VERSION ""

NS_ :

BS_:

BU_: XXX

BO_ 2684348833 EEC1: 8 Vector__XXX
 SG_ EngineSpeed : 24|16@1+ (0.125,0) [0|8031.875] "rpm" Vector__XXX

BO_ 136 CRUISE_RELATED: 8 XXX
 SG_ CRUISE_TORQUE_RELATED_INV : 2|9@0+ (1,0) [0|4000] "" XXX
 SG_ ENGINE_TORQUE_RELATED : 45|16@0+ (1,0) [0|50000] "" XXX

BO_ 139 STEER_ANGLE: 48 XXX
 SG_ STEER_ANGLE : 55|16@0+ (0.05,0) [0|500] "" XXX
 SG_ STEER_ANGLE_REPEAT : 208|16@0+ (0.05,0) [0|500] "" XXX

BO_ 140 PEDAL_THROTTLE: 48 XXX
 SG_ ACCEL_PEDAL_POSITION: 43|10@0+ (1,0) [0|1000] "" XXX
 SG_ ACCEL_PEDAL_POSITION_REPEAT: 49|10@0+ (1,0) [0|200] "" XXX
 SG_ RPM_RELATED: 86|12@0+ (0.05,0) [0|4000] "" XXX
 SG_ WHEEL_TORQUE_CMD_RELATED: 139|16@0+ (0.05,0) [0|100000] "" XXX
 SG_ RPM: 167|16@0+ (0.14285,0) [0|100000] "" XXX
 SG_ WHEEL_TORQUE_CMD_RELATED_2: 183|10@0+ (0.05,0) [0|100000] "" XXX

BO_ 141 STEERING_WHEEL: 24 XXX
 SG_ STEER_ANGLE: 55|18@0+ (1,0) [0|140000] "" XXX
 SG_ STEER_RATE: 66|12@0+ (1,0) [0|4000] "" XXX
 SG_ STEER_RELATED_YAW: 86|11@0+ (1,0) [0|1000] "" XXX

BO_ 168 STEERING_2: 24 XXX
 SG_ STEER_ANGLE: 55|12@0+ (1,0) [0|140000] "" XXX
 SG_ STEER_RATE: 79|16@0+ (1,0) [0|4000] "" XXX

BO_ 286 TWO_EIGHTY_SIX: 4 XXX
 SG_ WHEEL_TORQUE_CMD : 5|15@0+ (1,0) [0|100] "" XXX

BO_ 303 SPEED: 24 XXX
 SG_ WHEEL_TORQUE: 60|12@0+ (1,0) [0|4000] "" XXX
 SG_ SPEED : 77|12@0+ (0.05,0) [0|65535] "kph" XXX

BO_ 308 CRUISE: 64 XXX
 SG_ CRUISE_TORQUE_STATE : 57|4@0+ (1,0) [0|16] "" XXX
 SG_ WHEEL_TORQUE_CMD : 68|12@0+ (1,0) [0|4000] "" XXX
 SG_ STEER_ANGLE_BUT_NOT : 151|16@0+ (1,0) [0|40000] "" XXX
 SG_ BRAKE_TORQUE_ACTIVE : 160|1@0+ (1,0) [0|1] "" XXX
 SG_ BRAKE_TORQUE_CMD : 170|10@0+ (1,0) [0|1000] "" XXX
 SG_ CRUISE_STATE : 306|5@0+ (1,0) [0|32] "" XXX
 SG_ CRUISE_ENGAGED : 321|1@0+ (1,0) [0|1] "" XXX

BO_ 427 ACCEL_STEER: 64 XXX
 SG_ MYSTERY_STATE : 52|4@0+ (1,0) [0|16] "" XXX
 SG_ STEERING_RATE : 63|7@0+ (1,-75) [0|40000] "" XXX
 SG_ STEER_ANGLE : 71|12@0+ (1,-1500) [0|4000] "" XXX
 SG_ ACCEL_X : 231|12@0+ (0.1,-2000) [0|4000] "" XXX
 SG_ ACCEL_X_REPEAT : 235|12@0+ (0.1,-2000) [0|4000] "" XXX
 SG_ YAW : 255|12@0+ (0.1,-2000) [0|4000] "" XXX
 SG_ YAW_REPEAT : 259|12@0+ (0.1,-2000) [0|4000] "" XXX
 SG_ STEER_ANGLE_REPEAT : 315|12@0+ (1,-3050) [0|4000] "" XXX
 SG_ STEER_ANGLE_BUT_NOT : 343|15@0+ (1,0) [0|40000] "" XXX
 SG_ MYSTERY_STATE2 : 344|1@0+ (1,0) [0|1] "" XXX
 SG_ STEER_ANGLE_REPEAT_AGAIN : 359|11@0+ (1,-1000) [0|2000] "" XXX

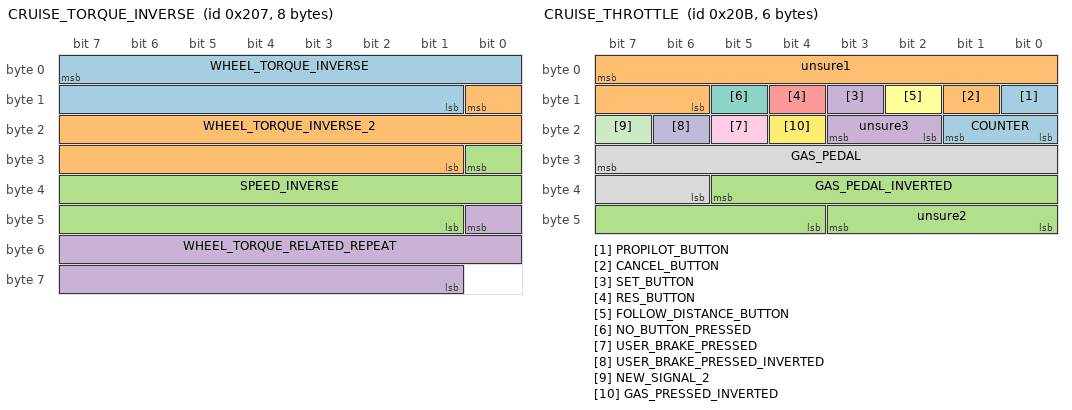
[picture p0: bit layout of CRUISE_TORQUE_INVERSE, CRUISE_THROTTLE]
BO_ 519 CRUISE_TORQUE_INVERSE: 8 XXX
 SG_ WHEEL_TORQUE_INVERSE : 7|15@0+ (1,0) [0|2000] "" XXX
 SG_ WHEEL_TORQUE_INVERSE_2 : 8|16@0+ (1,0) [0|20000] "" XXX
 SG_ SPEED_INVERSE : 24|16@0+ (1,0) [0|60000] "" XXX
 SG_ WHEEL_TORQUE_RELATED_REPEAT : 40|16@0+ (1,0) [0|60000] "" XXX

BO_ 523 CRUISE_THROTTLE: 6 XXX
 SG_ PROPILOT_BUTTON : 8|1@0+ (1,0) [0|1] "" XXX
 SG_ CANCEL_BUTTON : 9|1@0+ (1,0) [0|1] "" XXX
 SG_ GAS_PEDAL_INVERTED : 37|10@0+ (1,0) [0|1023] "" XXX
 SG_ SET_BUTTON : 11|1@0+ (1,0) [0|1] "" XXX
 SG_ RES_BUTTON : 12|1@0+ (1,0) [0|1] "" XXX
 SG_ FOLLOW_DISTANCE_BUTTON : 10|1@0+ (1,0) [0|1] "" XXX
 SG_ NO_BUTTON_PRESSED : 13|1@0+ (1,0) [0|1] "" XXX
 SG_ GAS_PEDAL : 31|10@0+ (1,0) [0|255] "" XXX
 SG_ USER_BRAKE_PRESSED : 21|1@0+ (1,0) [0|1] "" XXX
 SG_ USER_BRAKE_PRESSED_INVERTED : 22|1@0+ (1,0) [0|3] "" XXX
 SG_ NEW_SIGNAL_2 : 23|1@0+ (1,0) [0|1] "" XXX
 SG_ GAS_PRESSED_INVERTED : 20|1@0+ (1,0) [0|255] "" XXX
 SG_ COUNTER : 17|2@0+ (1,0) [0|3] "" XXX
 SG_ unsure1 : 7|10@0+ (1,0) [0|1023] "" XXX
 SG_ unsure2 : 43|4@0+ (1,0) [0|1] "" XXX
 SG_ unsure3 : 19|2@0+ (1,0) [0|3] "" XXX

BO_ 550 WHEEL_ENCODERS: 64 XXX
 SG_ WHEEL_SPEED_FL : 111|16@0+ (0.0057,0) [0|65535] "" XXX
 SG_ WHEEL_SPEED_FR : 127|16@0+ (0.0057,0) [0|65535] "" XXX
 SG_ WHEEL_SPEED_FRONT : 143|16@0+ (0.01,0) [0|65535] "" XXX
 SG_ WHEEL_SPEED_RR : 287|16@0+ (0.0057,0) [0|65535] "" XXX
 SG_ WHEEL_SPEED_RL : 303|16@0+ (0.0057,0) [0|65535] "" XXX
 SG_ WHEEL_SPEED_REAR : 319|16@0+ (0.01,0) [0|65535] "" XXX

BO_ 689 PROPILOT_HUD: 8 XXX
 SG_ LARGE_WARNING_FLASHING : 9|1@0+ (1,0) [0|1] "" XXX
 SG_ SIDE_RADAR_ERROR_FLASHING1 : 10|1@0+ (1,0) [0|1] "" XXX
 SG_ SIDE_RADAR_ERROR_FLASHING2 : 11|1@0+ (1,0) [0|1] "" XXX
 SG_ RIGHT_LANE_YELLOW_FLASH : 12|1@0+ (1,0) [0|1] "" XXX
 SG_ LEFT_LANE_YELLOW_FLASH : 13|1@0+ (1,0) [0|1] "" XXX
 SG_ LEAD_CAR : 14|1@0+ (1,0) [0|1] "" XXX
 SG_ LEAD_CAR_ERROR : 15|1@0+ (1,0) [0|1] "" XXX
 SG_ FRONT_RADAR_ERROR : 16|1@0+ (1,0) [0|1] "" XXX
 SG_ FRONT_RADAR_ERROR_FLASHING : 17|1@0+ (1,0) [0|1] "" XXX
 SG_ RIGHT_LANE_GREEN : 24|1@0+ (1,0) [0|1] "" XXX
 SG_ LEFT_LANE_GREEN : 25|1@0+ (1,0) [0|1] "" XXX
 SG_ SIDE_RADAR_ERROR_FLASHING3 : 27|1@0+ (1,0) [0|1] "" XXX
 SG_ LKAS_ERROR_FLASHING : 29|1@0+ (1,0) [0|1] "" XXX
 SG_ SAFETY_SHIELD_ACTIVE : 44|1@0+ (1,0) [0|1] "" XXX
 SG_ LARGE_STEERING_WHEEL_ICON : 61|2@0+ (1,0) [0|3] "" XXX
 SG_ RIGHT_LANE_GREEN_FLASH : 62|1@0+ (1,0) [0|1] "" XXX
 SG_ LEFT_LANE_GREEN_FLASH : 63|1@0+ (1,0) [0|1] "" XXX
 SG_ FOLLOW_DISTANCE : 3|2@0+ (1,0) [0|3] "" XXX
 SG_ AUDIBLE_TONE : 47|3@0+ (1,0) [0|8] "" XXX
 SG_ SPEED_SET_ICON : 7|2@0+ (1,0) [0|3] "" XXX
 SG_ SMALL_STEERING_WHEEL_ICON : 42|3@0+ (1,0) [0|7] "" XXX
 SG_ SET_SPEED : 39|8@0+ (1,0) [0|255] "" XXX
 SG_ unknown02 : 1|2@0+ (1,0) [0|3] "" XXX
 SG_ unknown05 : 5|2@0+ (1,0) [0|3] "" XXX
 SG_ unknown08 : 8|7@0+ (1,0) [0|63] "" XXX
 SG_ unknown26 : 26|1@0+ (1,0) [0|1] "" XXX
 SG_ unknown28 : 28|1@0+ (1,0) [0|1] "" XXX
 SG_ unknown31 : 31|2@0+ (1,0) [0|3] "" XXX
 SG_ unknown43 : 43|1@0+ (1,0) [0|1] "" XXX
 SG_ unknown55 : 55|8@0+ (1,0) [0|63] "" XXX
 SG_ unknown59 : 59|4@0+ (1,0) [0|15] "" XXX

BO_ 771 SONAR : 64 XXX
 SG_ SONAR1 : 135|6@0+ (0.0833,0) [0|300] "" XXX
 SG_ SONAR2 : 143|6@0+ (0.0833,0) [0|300] "" XXX
 SG_ SONAR3 : 151|6@0+ (0.0833,0) [0|300] "" XXX
 SG_ SONAR4 : 159|6@0+ (0.0833,0) [0|300] "" XXX
 SG_ SONAR5 : 167|6@0+ (0.0833,0) [0|300] "" XXX
 SG_ SONAR6 : 175|6@0+ (0.0833,0) [0|300] "" XXX

 SG_ SONAR7 : 223|6@0+ (0.0833,0) [0|300] "" XXX
 SG_ SONAR8 : 231|6@0+ (0.0833,0) [0|300] "" XXX
 SG_ SONAR9 : 239|6@0+ (0.0833,0) [0|300] "" XXX
 SG_ SONAR10 : 247|6@0+ (0.0833,0) [0|300] "" XXX
 SG_ SONAR11 : 255|6@0+ (0.0833,0) [0|300] "" XXX
 SG_ SONAR12 : 263|6@0+ (0.0833,0) [0|300] "" XXX

 SG_ SONAR13 : 311|6@0+ (0.0833,0) [0|300] "" XXX
 SG_ SONAR14 : 319|6@0+ (0.0833,0) [0|300] "" XXX
 SG_ SONAR15 : 327|6@0+ (0.0833,0) [0|300] "" XXX
 SG_ SONAR16 : 335|6@0+ (0.0833,0) [0|300] "" XXX
 SG_ SONAR17 : 343|6@0+ (0.0833,0) [0|300] "" XXX
 SG_ SONAR18 : 351|6@0+ (0.0833,0) [0|300] "" XXX
 SG_ SONAR19 : 359|6@0+ (0.0833,0) [0|300] "" XXX
 SG_ SONAR20 : 367|6@0+ (0.0833,0) [0|300] "" XXX

BO_ 768 STEER_TORQUE_SENSOR2: 2 XXX
 SG_ STEERING_TORQUE : 6|7@0+ (1,0) [0|127] "" XXX
 SG_ STEERING_PRESSED : 15|1@0+ (-1,1) [0|7] "" XXX

BO_ 783 CRUISE_STATE: 3 XXX
 SG_ CRUISE_ENABLED : 3|1@0+ (1,0) [0|1] "" XXX

BO_ 1055 GEARBOX: 2 XXX
 SG_ SPORTS_MODE : 13|1@0+ (1,0) [0|1] "" XXX
 SG_ GEAR_SHIFTER : 5|3@0+ (1,0) [0|255] "" XXX

BO_ 1081 ODOMETER: 6 XXX
 SG_ UNKNOWN1 : 7|8@0+ (1,-75) [0|200] "" XXX
 SG_ ODOMETER : 31|12@0+ (1,0) [0|1000000] "m" XXX

BO_ 1105 UNKNOWN_STATE : 24 XXX
 SG_ MYSTERY_NOISY_DISCRETE_STATE : 64|4@0+ (1,0) [0|100] "" XXX

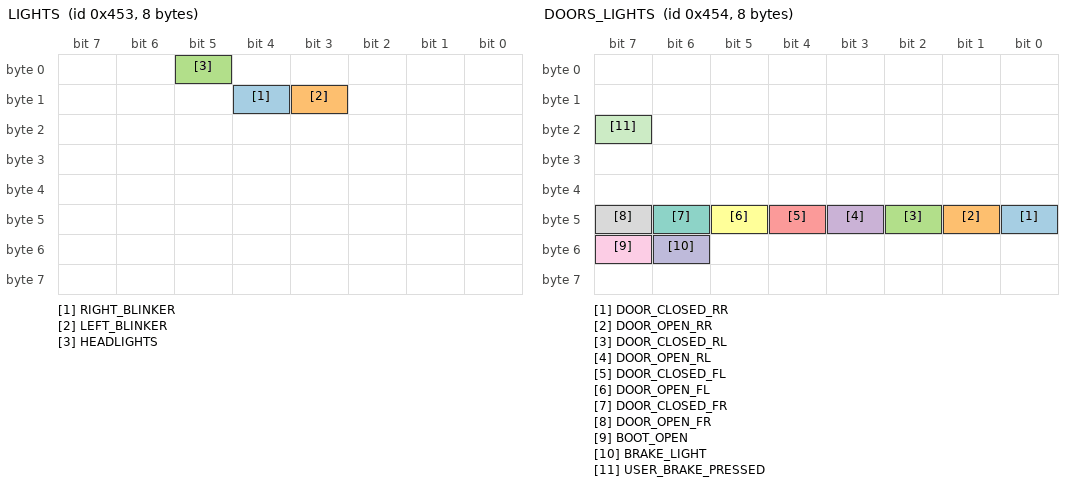
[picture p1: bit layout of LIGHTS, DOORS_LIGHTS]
BO_ 1107 LIGHTS: 8 XXX
 SG_ RIGHT_BLINKER : 12|1@0+ (1,0) [0|1] "" XXX
 SG_ LEFT_BLINKER : 11|1@0+ (1,0) [0|1] "" XXX
 SG_ HEADLIGHTS : 5|1@0+ (1,0) [0|1] "" XXX

BO_ 1108 DOORS_LIGHTS: 8 XXX
 SG_ DOOR_CLOSED_RR : 40|1@0+ (1,0) [0|1] "" XXX
 SG_ DOOR_OPEN_RR : 41|1@0+ (1,0) [0|1] "" XXX
 SG_ DOOR_CLOSED_RL : 42|1@0+ (1,0) [0|1] "" XXX
 SG_ DOOR_OPEN_RL : 43|1@0+ (1,0) [0|1] "" XXX
 SG_ DOOR_CLOSED_FL : 44|1@0+ (1,0) [0|1] "" XXX
 SG_ DOOR_OPEN_FL : 45|1@0+ (1,0) [0|1] "" XXX
 SG_ DOOR_CLOSED_FR : 46|1@0+ (1,0) [0|3] "" XXX
 SG_ DOOR_OPEN_FR : 47|1@0+ (1,0) [0|3] "" XXX
 SG_ BOOT_OPEN : 55|1@0+ (1,0) [0|1] "" XXX
 SG_ BRAKE_LIGHT : 54|1@0+ (1,0) [0|1] "" XXX
 SG_ USER_BRAKE_PRESSED : 23|1@0+ (1,0) [0|1] "" XXX

BO_ 1119 LKAS_SETTINGS: 20 XXX
 SG_ LKAS_LDW_ON : 48|1@0+ (1,0) [0|1] "" XXX

BO_ 1228 PROPILOT_HUD_INFO_MSG: 8 XXX
 SG_ NA_HIGH_ACCEL_TEMP : 0|1@0+ (1,0) [0|1] "" XXX
 SG_ SIDE_RADAR_NA_HIGH_CABIN_TEMP : 8|1@0+ (1,0) [0|1] "" XXX
 SG_ SIDE_RADAR_MALFUNCTION : 11|1@0+ (1,0) [0|1] "" XXX
 SG_ LKAS_MALFUNCTION : 12|1@0+ (1,0) [0|1] "" XXX
 SG_ FRONT_RADAR_MALFUNCTION : 13|1@0+ (1,0) [0|1] "" XXX
 SG_ SIDE_RADAR_NA_CLEAN_REAR_CAMERA : 14|1@0+ (1,0) [0|1] "" XXX
 SG_ NA_POOR_ROAD_CONDITIONS : 16|1@0+ (1,0) [0|1] "" XXX
 SG_ CURRENTLY_UNAVAILABLE : 17|1@0+ (1,0) [0|1] "" XXX
 SG_ SAFETY_SHIELD_OFF : 18|1@0+ (1,0) [0|1] "" XXX
 SG_ FRONT_COLLISION_NA_FRONT_RADAR_OBSTRUCTION : 20|1@0+ (1,0) [0|1] "" XXX
 SG_ PEDAL_MISSAPPLICATION_SYSTEM_ACTIVATED : 24|1@0+ (1,0) [0|1] "" XXX
 SG_ SIDE_IMPACT_NA_RADAR_OBSTRUCTION : 25|1@0+ (1,0) [0|1] "" XXX
 SG_ WARNING_DO_NOT_ENTER : 33|1@0+ (1,0) [0|1] "" XXX
 SG_ SIDE_IMPACT_SYSTEM_OFF : 34|1@0+ (1,0) [0|1] "" XXX
 SG_ SIDE_IMPACT_MALFUNCTION : 35|1@0+ (1,0) [0|1] "" XXX
 SG_ FRONT_COLLISION_MALFUNCTION : 36|1@0+ (1,0) [0|1] "" XXX
 SG_ SIDE_RADAR_MALFUNCTION2 : 37|1@0+ (1,0) [0|1] "" XXX
 SG_ LKAS_MALFUNCTION2 : 38|1@0+ (1,0) [0|1] "" XXX
 SG_ FRONT_RADAR_MALFUNCTION2 : 39|1@0+ (1,0) [0|1] "" XXX
 SG_ PROPILOT_NA_MSGS : 42|3@0+ (1,0) [0|7] "" XXX
 SG_ BOTTOM_MSG : 45|3@0+ (1,0) [0|7] "" XXX
 SG_ HANDS_ON_WHEEL_WARNING : 47|1@0+ (1,0) [0|1] "" XXX
 SG_ WARNING_STEP_ON_BRAKE_NOW : 51|1@0+ (1,0) [0|1] "" XXX
 SG_ PROPILOT_NA_FRONT_CAMERA_OBSTRUCTED : 52|1@0+ (1,0) [0|1] "" XXX
 SG_ PROPILOT_NA_HIGH_CABIN_TEMP : 53|1@0+ (1,0) [0|1] "" XXX
 SG_ WARNING_PROPILOT_MALFUNCTION : 54|1@0+ (1,0) [0|3] "" XXX
 SG_ ACC_UNAVAILABLE_HIGH_CABIN_TEMP : 62|1@0+ (1,0) [0|1] "" XXX
 SG_ ACC_NA_FRONT_CAMERA_IMPARED : 63|1@0+ (1,0) [0|1] "" XXX
 SG_ unknown07 : 7|7@0+ (1,0) [0|127] "" XXX
 SG_ unknown10 : 10|2@0+ (1,0) [0|3] "" XXX
 SG_ unknown15 : 15|1@0+ (1,0) [0|1] "" XXX
 SG_ unknown23 : 23|3@0+ (1,0) [0|7] "" XXX
 SG_ unknown19 : 19|1@0+ (1,0) [0|1] "" XXX
 SG_ unknown31 : 31|6@0+ (1,0) [0|63] "" XXX
 SG_ unknown32 : 32|1@0+ (1,0) [0|1] "" XXX
 SG_ unknown46 : 46|1@0+ (1,0) [0|1] "" XXX
 SG_ unknown50 : 50|3@0+ (1,0) [0|7] "" XXX
 SG_ unknown55 : 55|1@0+ (1,0) [0|1] "" XXX
 SG_ unknown61 : 61|6@0+ (1,0) [0|63] "" XXX

//BO_ 1227 LKAS_SETTINGS: 8 XXX
// SG_ LKAS_ENABLED : 51|1@0+ (1,0) [0|1] "" XXX

BO_ 1273 HUD: 7 XXX
 SG_ SEATBELT_DRIVER_LATCHED : 25|1@0+ (1,0) [0|1] "" XXX
 SG_ SPEED_MPH : 5|1@0+ (1,0) [0|1] "" XXX

BO_ 1459 GEAR: 4 XXX
 SG_ REVERSE : 8|1@0+ (1,0) [0|1] "" XXX

//VAL_ 1055 GEAR_SHIFTER 6 "L" 4 "D" 3 "N" 2 "R" 1 "P" ;
VAL_ 1228 PROPILOT_NA_MSGS 0 "NO_MSG" 1 "NA_FRONT_CAMERA_IMPARED" 2 "STEERING_ASSIST_ON_STANDBY" 3 "NA_PARKING_ASSIST_ENABLED" 4 "STEER_ASSIST_CURRENTLY_NA" 5 "NA_BAD_WEATHER" 6 "NA_PARK_BRAKE_ON" 7 "NA_SEATBELT_NOT_FASTENED" ;
VAL_ 1228 BOTTOM_MSG 0 "OK_STEER_ASSIST_SETTINGS" 1 "NO_MSG" 2 "PRESS_SET_TO_SET_SPEED" 3 "PRESS_RES_SET_TO_CHANGE_SPEED" 4 "PRESS_RES_TO_RESTART" 5 "NO_MSG" 6 "CRUISE_NOT_AVAIL" 7 "NO_MSG" ;
VAL_ 689 FOLLOW_DISTANCE 0 "NO_FOLLOW_DISTANCE" 1 "FOLLOW_DISTANCE_1" 2 "FOLLOW_DISTANCE_2" 3 "FOLLOW_DISANCE_3" ;
VAL_ 689 AUDIBLE_TONE 0 "NO_TONE" 1 "CONT" 2 "FAST_BEEP_CONT" 3 "TRIPLE_FAST_BEEP_CONT" 4 "SLOW_BEEP_CONT" 5 "QUAD_SLOW_BEEP_CONT" 6 "SINGLE_BEEP_ONCE" 7 "DOUBLE_BEEP_ONCE" ;
VAL_ 689 SMALL_STEERING_WHEEL_ICON 0 "NO_ICON" 1 "GRAY_ICON" 2 "GRAY_ICON_FLASHING" 3 "GREEN_ICON" 4 "GREEN_ICON_FLASHING" 5 "RED_ICON" 6 "RED_ICON_FLASHING" 7 "YELLOW_ICON" ;
VAL_ 689 LARGE_STEERING_WHEEL_ICON 0 "NO_STEERINGWHEEL" 1 "GRAY_STEERINGWHEEL" 2 "GREEN_STEERINGWHEEL" 3 "GREEN_STEERINGWHEEL_FLASHING" ;
